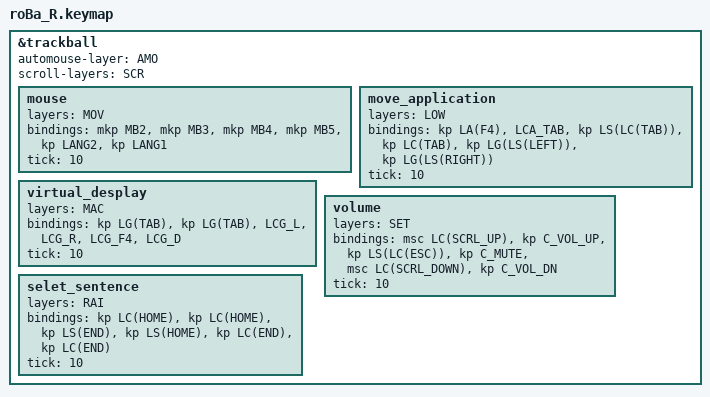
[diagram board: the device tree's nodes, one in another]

#include "roBa_L.keymap"
#include "/__w/zmk-config-roBa/zmk-config-roBa/boards/shields/roBa/roBa_R.overlay"

// トラックボールの設定(overlay)
&trackball {
    automouse-layer = <AMO>;
    scroll-layers = <SCR>;
    // snipe-layers = <3>;
    //num_arrow {
    //    layers = <MOV>;
    //    bindings =
    //        <&kp N7>,    // up left
    //        <&kp N9>,    // up right
    //        <&kp N4>,    // left
    //        <&kp N6>,    // right
    //        <&kp N1>,    // down left
    //        <&kp N3>;    // down right
    //    tick = <300>;
    //};
    mouse {
        layers = <MOV>;
        bindings =
            <&mkp MB2>,
            <&mkp MB3>,
            <&mkp MB4>,
            <&mkp MB5>,
            <&kp LANG2>,
            <&kp LANG1>;
        tick = <10>;
    };
    move_application {
        layers = <LOW>;
        bindings =
            <&kp LA(F4)>,
            <&LCA_TAB>,
            <&kp LS(LC(TAB))>,
            <&kp LC(TAB)>,
            <&kp LG(LS(LEFT))>,
            <&kp LG(LS(RIGHT))>;
        tick = <10>;
    };
    virtual_desplay {
        layers = <MAC>;
        bindings =
            <&kp LG(TAB)>,
            <&kp LG(TAB)>,
            <&LCG_L>,
            <&LCG_R>,
            <&LCG_F4>,
            <&LCG_D>;
        tick = <10>;
    };
    volume {
        layers = <SET>;
        bindings =
            <&msc LC(SCRL_UP)>,
            <&kp C_VOL_UP>,
            <&kp LS(LC(ESC))>,
            <&kp C_MUTE>,
            <&msc LC(SCRL_DOWN)>,
            <&kp C_VOL_DN>;
        tick = <10>;
    };
    selet_sentence {
        layers = <RAI>;
        bindings =
            <&kp LC(HOME)>,
            <&kp LC(HOME)>,
            <&kp LS(END)>,
            <&kp LS(HOME)>,
            <&kp LC(END)>,
            <&kp LC(END)>;
        tick = <10>;
    };
};
